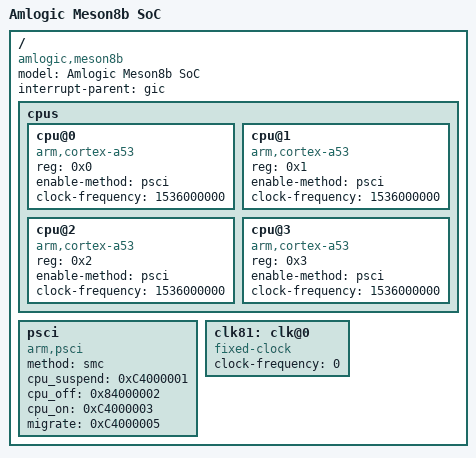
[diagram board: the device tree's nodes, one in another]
/*-
 * Copyright (c) 2015 John Wehle <john@feith.com>
 * All rights reserved.
 *
 * Redistribution and use in source and binary forms, with or without
 * modification, are permitted provided that the following conditions
 * are met:
 * 1. Redistributions of source code must retain the above copyright
 *    notice, this list of conditions and the following disclaimer.
 * 2. Redistributions in binary form must reproduce the above copyright
 *    notice, this list of conditions and the following disclaimer in the
 *    documentation and/or other materials provided with the distribution.
 *
 * THIS SOFTWARE IS PROVIDED BY THE AUTHOR AND CONTRIBUTORS ``AS IS'' AND
 * ANY EXPRESS OR IMPLIED WARRANTIES, INCLUDING, BUT NOT LIMITED TO, THE
 * IMPLIED WARRANTIES OF MERCHANTABILITY AND FITNESS FOR A PARTICULAR PURPOSE
 * ARE DISCLAIMED. IN NO EVENT SHALL THE AUTHOR OR CONTRIBUTORS BE LIABLE
 * FOR ANY DIRECT, INDIRECT, INCIDENTAL, SPECIAL, EXEMPLARY, OR CONSEQUENTIAL
 * DAMAGES (INCLUDING, BUT NOT LIMITED TO, PROCUREMENT OF SUBSTITUTE GOODS
 * OR SERVICES; LOSS OF USE, DATA, OR PROFITS; OR BUSINESS INTERRUPTION)
 * HOWEVER CAUSED AND ON ANY THEORY OF LIABILITY, WHETHER IN CONTRACT, STRICT
 * LIABILITY, OR TORT (INCLUDING NEGLIGENCE OR OTHERWISE) ARISING IN ANY WAY
 * OUT OF THE USE OF THIS SOFTWARE, EVEN IF ADVISED OF THE POSSIBILITY OF
 * SUCH DAMAGE.
 *
 * $FreeBSD$
 */

/include/ "meson.dtsi"

/ {
	model = "Amlogic Meson8b SoC";
	compatible = "amlogic,meson8b";

	interrupt-parent = <&gic>;

	cpus {
		#address-cells = <1>;
		#size-cells = <0>;

		cpu@0 {
			device_type = "cpu";
			compatible = "arm,cortex-a53","arm,armv8";
			reg = <0x0>;
			enable-method = "psci";
			//next-level-cache = <&L2>;
			clock-frequency = <1536000000>;
		};

		cpu@1 {
			device_type = "cpu";
			compatible = "arm,cortex-a53","arm,armv8";
			reg = <0x1>;
			enable-method = "psci";
			//next-level-cache = <&L2>;
			clock-frequency = <1536000000>;
		};
		cpu@2 {
			device_type = "cpu";
			compatible = "arm,cortex-a53","arm,armv8";
			reg = <0x2>;
			enable-method = "psci";
			//next-level-cache = <&L2>;
			clock-frequency = <1536000000>;
		};

		cpu@3 {
			device_type = "cpu";
			compatible = "arm,cortex-a53","arm,armv8";
			reg = <0x3>;
			enable-method = "psci";
			//next-level-cache = <&L2>;
			clock-frequency = <1536000000>;
		};
/*
*/
	};

	psci {
		compatible = "arm,psci";
		method = "smc";
		cpu_suspend = <0xC4000001>;
		cpu_off = <0x84000002>;
		cpu_on = <0xC4000003>;
		migrate = <0xC4000005>;
	};


	clk81: clk@0 {
		#clock-cells = <0>;
		compatible = "fixed-clock";
		clock-frequency = <0>;
	};
};

/*
&L2 {
	interrupts = <0 143 1>;
};
*/
